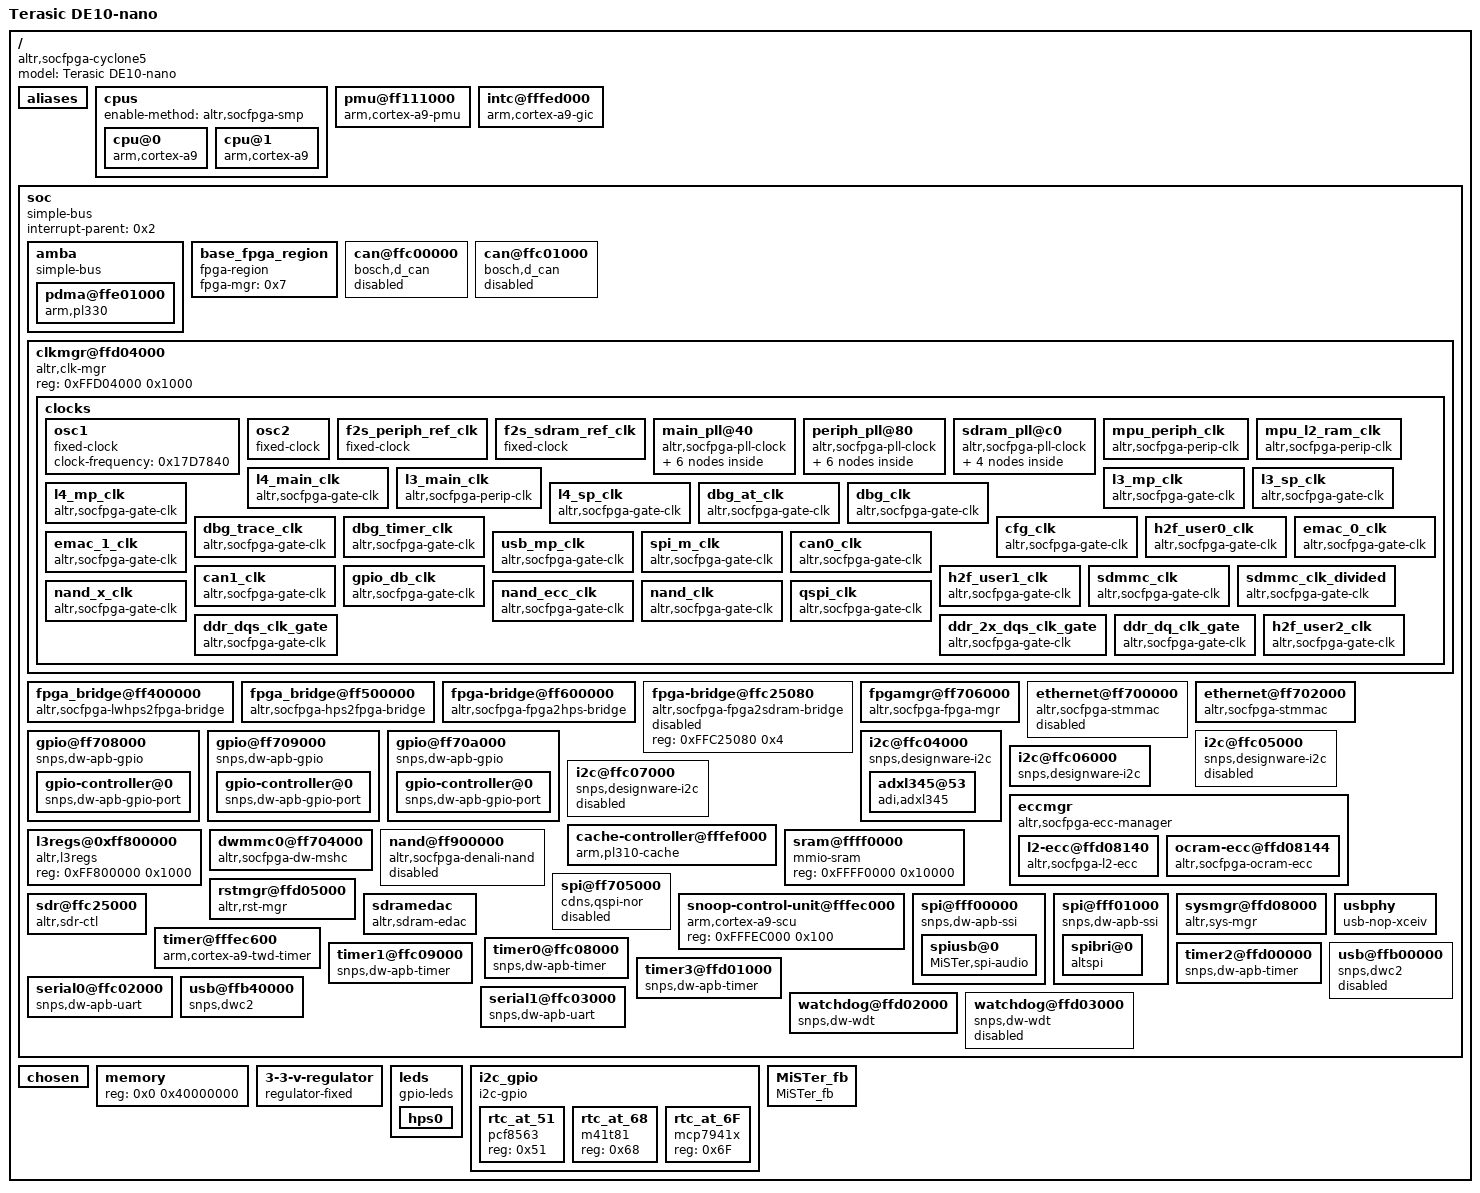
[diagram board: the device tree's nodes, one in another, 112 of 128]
/dts-v1/;
// version: 17
// last_comp_version: 16
// boot_cpuid_phys: 0x0

/memreserve/ 0 0x1000;
/ {
    #address-cells = <0x1>;
    #size-cells = <0x1>;
    model = "Terasic DE10-nano";
    compatible = "altr,socfpga-cyclone5", "altr,socfpga";
    aliases {
        serial0 = "/soc/serial0@ffc02000";
        serial1 = "/soc/serial1@ffc03000";
        timer0 = "/soc/timer0@ffc08000";
        timer1 = "/soc/timer1@ffc09000";
        timer2 = "/soc/timer2@ffd00000";
        timer3 = "/soc/timer3@ffd01000";
        ethernet0 = "/soc/ethernet@ff702000";
    };
    cpus {
        #address-cells = <0x1>;
        #size-cells = <0x0>;
        enable-method = "altr,socfpga-smp";
        cpu@0 {
            compatible = "arm,cortex-a9";
            device_type = "cpu";
            reg = <0x0>;
            next-level-cache = <0x1>;
            phandle = <0x3>;
        };
        cpu@1 {
            compatible = "arm,cortex-a9";
            device_type = "cpu";
            reg = <0x1>;
            next-level-cache = <0x1>;
            phandle = <0x4>;
        };
    };
    pmu@ff111000 {
        compatible = "arm,cortex-a9-pmu";
        interrupt-parent = <0x2>;
        interrupts = <0x0 0xB0 0x4 0x0 0xB1 0x4>;
        interrupt-affinity = <0x3 0x4>;
        reg = <0xFF111000 0x1000 0xFF113000 0x1000>;
    };
    intc@fffed000 {
        compatible = "arm,cortex-a9-gic";
        #interrupt-cells = <0x3>;
        interrupt-controller;
        reg = <0xFFFED000 0x1000 0xFFFEC100 0x100>;
        phandle = <0x2>;
    };
    soc {
        #address-cells = <0x1>;
        #size-cells = <0x1>;
        compatible = "simple-bus";
        device_type = "soc";
        interrupt-parent = <0x2>;
        ranges;
        amba {
            compatible = "simple-bus";
            #address-cells = <0x1>;
            #size-cells = <0x1>;
            ranges;
            pdma@ffe01000 {
                compatible = "arm,pl330", "arm,primecell";
                reg = <0xFFE01000 0x1000>;
                interrupts = <0x0 0x68 0x4 0x0 0x69 0x4 0x0 0x6A 0x4 0x0 0x6B 0x4 0x0 0x6C 0x4 0x0 0x6D 0x4 0x0 0x6E 0x4 0x0 0x6F 0x4>;
                #dma-cells = <0x1>;
                #dma-channels = <0x8>;
                #dma-requests = <0x20>;
                clocks = <0x5>;
                clock-names = "apb_pclk";
                resets = <0x6 0x3C>;
                reset-names = "dma";
            };
        };
        base_fpga_region {
            compatible = "fpga-region";
            fpga-mgr = <0x7>;
            #address-cells = <0x1>;
            #size-cells = <0x1>;
        };
        can@ffc00000 {
            compatible = "bosch,d_can";
            reg = <0xFFC00000 0x1000>;
            interrupts = <0x0 0x83 0x4 0x0 0x84 0x4 0x0 0x85 0x4 0x0 0x86 0x4>;
            clocks = <0x8>;
            resets = <0x6 0x37>;
            status = "disabled";
        };
        can@ffc01000 {
            compatible = "bosch,d_can";
            reg = <0xFFC01000 0x1000>;
            interrupts = <0x0 0x87 0x4 0x0 0x88 0x4 0x0 0x89 0x4 0x0 0x8A 0x4>;
            clocks = <0x9>;
            resets = <0x6 0x38>;
            status = "disabled";
        };
        clkmgr@ffd04000 {
            compatible = "altr,clk-mgr";
            reg = <0xFFD04000 0x1000>;
            clocks {
                #address-cells = <0x1>;
                #size-cells = <0x0>;
                osc1 {
                    #clock-cells = <0x0>;
                    compatible = "fixed-clock";
                    clock-frequency = <0x17D7840>;
                    phandle = <0xA>;
                };
                osc2 {
                    #clock-cells = <0x0>;
                    compatible = "fixed-clock";
                    phandle = <0xC>;
                };
                f2s_periph_ref_clk {
                    #clock-cells = <0x0>;
                    compatible = "fixed-clock";
                    phandle = <0xD>;
                };
                f2s_sdram_ref_clk {
                    #clock-cells = <0x0>;
                    compatible = "fixed-clock";
                    phandle = <0xF>;
                };
                main_pll@40 {
                    #address-cells = <0x1>;
                    #size-cells = <0x0>;
                    #clock-cells = <0x0>;
                    compatible = "altr,socfpga-pll-clock";
                    clocks = <0xA>;
                    reg = <0x40>;
                    phandle = <0xB>;
                    mpuclk@48 {
                        #clock-cells = <0x0>;
                        compatible = "altr,socfpga-perip-clk";
                        clocks = <0xB>;
                        div-reg = <0xE0 0x0 0x9>;
                        reg = <0x48>;
                        phandle = <0x11>;
                    };
                    mainclk@4c {
                        #clock-cells = <0x0>;
                        compatible = "altr,socfpga-perip-clk";
                        clocks = <0xB>;
                        div-reg = <0xE4 0x0 0x9>;
                        reg = <0x4C>;
                        phandle = <0x12>;
                    };
                    dbg_base_clk@50 {
                        #clock-cells = <0x0>;
                        compatible = "altr,socfpga-perip-clk";
                        clocks = <0xB 0xA>;
                        div-reg = <0xE8 0x0 0x9>;
                        reg = <0x50>;
                        phandle = <0x15>;
                    };
                    main_qspi_clk@54 {
                        #clock-cells = <0x0>;
                        compatible = "altr,socfpga-perip-clk";
                        clocks = <0xB>;
                        reg = <0x54>;
                        phandle = <0x1F>;
                    };
                    main_nand_sdmmc_clk@58 {
                        #clock-cells = <0x0>;
                        compatible = "altr,socfpga-perip-clk";
                        clocks = <0xB>;
                        reg = <0x58>;
                        phandle = <0x1B>;
                    };
                    cfg_h2f_usr0_clk@5c {
                        #clock-cells = <0x0>;
                        compatible = "altr,socfpga-perip-clk";
                        clocks = <0xB>;
                        reg = <0x5C>;
                        phandle = <0x17>;
                    };
                };
                periph_pll@80 {
                    #address-cells = <0x1>;
                    #size-cells = <0x0>;
                    #clock-cells = <0x0>;
                    compatible = "altr,socfpga-pll-clock";
                    clocks = <0xA 0xC 0xD>;
                    reg = <0x80>;
                    phandle = <0xE>;
                    emac0_clk@88 {
                        #clock-cells = <0x0>;
                        compatible = "altr,socfpga-perip-clk";
                        clocks = <0xE>;
                        reg = <0x88>;
                        phandle = <0x18>;
                    };
                    emac1_clk@8c {
                        #clock-cells = <0x0>;
                        compatible = "altr,socfpga-perip-clk";
                        clocks = <0xE>;
                        reg = <0x8C>;
                        phandle = <0x19>;
                    };
                    per_qsi_clk@90 {
                        #clock-cells = <0x0>;
                        compatible = "altr,socfpga-perip-clk";
                        clocks = <0xE>;
                        reg = <0x90>;
                        phandle = <0x20>;
                    };
                    per_nand_mmc_clk@94 {
                        #clock-cells = <0x0>;
                        compatible = "altr,socfpga-perip-clk";
                        clocks = <0xE>;
                        reg = <0x94>;
                        phandle = <0x1C>;
                    };
                    per_base_clk@98 {
                        #clock-cells = <0x0>;
                        compatible = "altr,socfpga-perip-clk";
                        clocks = <0xE>;
                        reg = <0x98>;
                        phandle = <0x14>;
                    };
                    h2f_usr1_clk@9c {
                        #clock-cells = <0x0>;
                        compatible = "altr,socfpga-perip-clk";
                        clocks = <0xE>;
                        reg = <0x9C>;
                        phandle = <0x1A>;
                    };
                };
                sdram_pll@c0 {
                    #address-cells = <0x1>;
                    #size-cells = <0x0>;
                    #clock-cells = <0x0>;
                    compatible = "altr,socfpga-pll-clock";
                    clocks = <0xA 0xC 0xF>;
                    reg = <0xC0>;
                    phandle = <0x10>;
                    ddr_dqs_clk@c8 {
                        #clock-cells = <0x0>;
                        compatible = "altr,socfpga-perip-clk";
                        clocks = <0x10>;
                        reg = <0xC8>;
                        phandle = <0x21>;
                    };
                    ddr_2x_dqs_clk@cc {
                        #clock-cells = <0x0>;
                        compatible = "altr,socfpga-perip-clk";
                        clocks = <0x10>;
                        reg = <0xCC>;
                        phandle = <0x22>;
                    };
                    ddr_dq_clk@d0 {
                        #clock-cells = <0x0>;
                        compatible = "altr,socfpga-perip-clk";
                        clocks = <0x10>;
                        reg = <0xD0>;
                        phandle = <0x23>;
                    };
                    h2f_usr2_clk@d4 {
                        #clock-cells = <0x0>;
                        compatible = "altr,socfpga-perip-clk";
                        clocks = <0x10>;
                        reg = <0xD4>;
                        phandle = <0x24>;
                    };
                };
                mpu_periph_clk {
                    #clock-cells = <0x0>;
                    compatible = "altr,socfpga-perip-clk";
                    clocks = <0x11>;
                    fixed-divider = <0x4>;
                    phandle = <0x33>;
                };
                mpu_l2_ram_clk {
                    #clock-cells = <0x0>;
                    compatible = "altr,socfpga-perip-clk";
                    clocks = <0x11>;
                    fixed-divider = <0x2>;
                };
                l4_main_clk {
                    #clock-cells = <0x0>;
                    compatible = "altr,socfpga-gate-clk";
                    clocks = <0x12>;
                    clk-gate = <0x60 0x0>;
                    phandle = <0x5>;
                };
                l3_main_clk {
                    #clock-cells = <0x0>;
                    compatible = "altr,socfpga-perip-clk";
                    clocks = <0x12>;
                    fixed-divider = <0x1>;
                };
                l3_mp_clk {
                    #clock-cells = <0x0>;
                    compatible = "altr,socfpga-gate-clk";
                    clocks = <0x12>;
                    div-reg = <0x64 0x0 0x2>;
                    clk-gate = <0x60 0x1>;
                    phandle = <0x13>;
                };
                l3_sp_clk {
                    #clock-cells = <0x0>;
                    compatible = "altr,socfpga-gate-clk";
                    clocks = <0x13>;
                    div-reg = <0x64 0x2 0x2>;
                };
                l4_mp_clk {
                    #clock-cells = <0x0>;
                    compatible = "altr,socfpga-gate-clk";
                    clocks = <0x12 0x14>;
                    div-reg = <0x64 0x4 0x3>;
                    clk-gate = <0x60 0x2>;
                    phandle = <0x28>;
                };
                l4_sp_clk {
                    #clock-cells = <0x0>;
                    compatible = "altr,socfpga-gate-clk";
                    clocks = <0x12 0x14>;
                    div-reg = <0x64 0x7 0x3>;
                    clk-gate = <0x60 0x3>;
                    phandle = <0x29>;
                };
                dbg_at_clk {
                    #clock-cells = <0x0>;
                    compatible = "altr,socfpga-gate-clk";
                    clocks = <0x15>;
                    div-reg = <0x68 0x0 0x2>;
                    clk-gate = <0x60 0x4>;
                    phandle = <0x16>;
                };
                dbg_clk {
                    #clock-cells = <0x0>;
                    compatible = "altr,socfpga-gate-clk";
                    clocks = <0x16>;
                    div-reg = <0x68 0x2 0x2>;
                    clk-gate = <0x60 0x5>;
                };
                dbg_trace_clk {
                    #clock-cells = <0x0>;
                    compatible = "altr,socfpga-gate-clk";
                    clocks = <0x15>;
                    div-reg = <0x6C 0x0 0x3>;
                    clk-gate = <0x60 0x6>;
                };
                dbg_timer_clk {
                    #clock-cells = <0x0>;
                    compatible = "altr,socfpga-gate-clk";
                    clocks = <0x15>;
                    clk-gate = <0x60 0x7>;
                };
                cfg_clk {
                    #clock-cells = <0x0>;
                    compatible = "altr,socfpga-gate-clk";
                    clocks = <0x17>;
                    clk-gate = <0x60 0x8>;
                };
                h2f_user0_clk {
                    #clock-cells = <0x0>;
                    compatible = "altr,socfpga-gate-clk";
                    clocks = <0x17>;
                    clk-gate = <0x60 0x9>;
                };
                emac_0_clk {
                    #clock-cells = <0x0>;
                    compatible = "altr,socfpga-gate-clk";
                    clocks = <0x18>;
                    clk-gate = <0xA0 0x0>;
                    phandle = <0x26>;
                };
                emac_1_clk {
                    #clock-cells = <0x0>;
                    compatible = "altr,socfpga-gate-clk";
                    clocks = <0x19>;
                    clk-gate = <0xA0 0x1>;
                    phandle = <0x27>;
                };
                usb_mp_clk {
                    #clock-cells = <0x0>;
                    compatible = "altr,socfpga-gate-clk";
                    clocks = <0x14>;
                    clk-gate = <0xA0 0x2>;
                    div-reg = <0xA4 0x0 0x3>;
                    phandle = <0x34>;
                };
                spi_m_clk {
                    #clock-cells = <0x0>;
                    compatible = "altr,socfpga-gate-clk";
                    clocks = <0x14>;
                    clk-gate = <0xA0 0x3>;
                    div-reg = <0xA4 0x3 0x3>;
                    phandle = <0x32>;
                };
                can0_clk {
                    #clock-cells = <0x0>;
                    compatible = "altr,socfpga-gate-clk";
                    clocks = <0x14>;
                    clk-gate = <0xA0 0x4>;
                    div-reg = <0xA4 0x6 0x3>;
                    phandle = <0x8>;
                };
                can1_clk {
                    #clock-cells = <0x0>;
                    compatible = "altr,socfpga-gate-clk";
                    clocks = <0x14>;
                    clk-gate = <0xA0 0x5>;
                    div-reg = <0xA4 0x9 0x3>;
                    phandle = <0x9>;
                };
                gpio_db_clk {
                    #clock-cells = <0x0>;
                    compatible = "altr,socfpga-gate-clk";
                    clocks = <0x14>;
                    clk-gate = <0xA0 0x6>;
                    div-reg = <0xA8 0x0 0x18>;
                };
                h2f_user1_clk {
                    #clock-cells = <0x0>;
                    compatible = "altr,socfpga-gate-clk";
                    clocks = <0x1A>;
                    clk-gate = <0xA0 0x7>;
                };
                sdmmc_clk {
                    #clock-cells = <0x0>;
                    compatible = "altr,socfpga-gate-clk";
                    clocks = <0xD 0x1B 0x1C>;
                    clk-gate = <0xA0 0x8>;
                    clk-phase = <0x0 0x87>;
                    phandle = <0x1D>;
                };
                sdmmc_clk_divided {
                    #clock-cells = <0x0>;
                    compatible = "altr,socfpga-gate-clk";
                    clocks = <0x1D>;
                    clk-gate = <0xA0 0x8>;
                    fixed-divider = <0x4>;
                    phandle = <0x2C>;
                };
                nand_x_clk {
                    #clock-cells = <0x0>;
                    compatible = "altr,socfpga-gate-clk";
                    clocks = <0xD 0x1B 0x1C>;
                    clk-gate = <0xA0 0x9>;
                    phandle = <0x1E>;
                };
                nand_ecc_clk {
                    #clock-cells = <0x0>;
                    compatible = "altr,socfpga-gate-clk";
                    clocks = <0x1E>;
                    clk-gate = <0xA0 0x9>;
                    phandle = <0x2F>;
                };
                nand_clk {
                    #clock-cells = <0x0>;
                    compatible = "altr,socfpga-gate-clk";
                    clocks = <0x1E>;
                    clk-gate = <0xA0 0xA>;
                    fixed-divider = <0x4>;
                    phandle = <0x2E>;
                };
                qspi_clk {
                    #clock-cells = <0x0>;
                    compatible = "altr,socfpga-gate-clk";
                    clocks = <0xD 0x1F 0x20>;
                    clk-gate = <0xA0 0xB>;
                    phandle = <0x30>;
                };
                ddr_dqs_clk_gate {
                    #clock-cells = <0x0>;
                    compatible = "altr,socfpga-gate-clk";
                    clocks = <0x21>;
                    clk-gate = <0xD8 0x0>;
                };
                ddr_2x_dqs_clk_gate {
                    #clock-cells = <0x0>;
                    compatible = "altr,socfpga-gate-clk";
                    clocks = <0x22>;
                    clk-gate = <0xD8 0x1>;
                };
                ddr_dq_clk_gate {
                    #clock-cells = <0x0>;
                    compatible = "altr,socfpga-gate-clk";
                    clocks = <0x23>;
                    clk-gate = <0xD8 0x2>;
                };
                h2f_user2_clk {
                    #clock-cells = <0x0>;
                    compatible = "altr,socfpga-gate-clk";
                    clocks = <0x24>;
                    clk-gate = <0xD8 0x3>;
                };
            };
        };
        fpga_bridge@ff400000 {
            compatible = "altr,socfpga-lwhps2fpga-bridge";
            reg = <0xFF400000 0x100000>;
            resets = <0x6 0x61>;
            clocks = <0x5>;
            status = "okay";
        };
        fpga_bridge@ff500000 {
            compatible = "altr,socfpga-hps2fpga-bridge";
            reg = <0xFF500000 0x10000>;
            resets = <0x6 0x60>;
            clocks = <0x5>;
            status = "okay";
        };
        fpga-bridge@ff600000 {
            compatible = "altr,socfpga-fpga2hps-bridge";
            reg = <0xFF600000 0x100000>;
            resets = <0x6 0x62>;
            clocks = <0x5>;
            status = "okay";
        };
        fpga-bridge@ffc25080 {
            compatible = "altr,socfpga-fpga2sdram-bridge";
            reg = <0xFFC25080 0x4>;
            status = "disabled";
        };
        fpgamgr@ff706000 {
            compatible = "altr,socfpga-fpga-mgr";
            reg = <0xFF706000 0x1000 0xFFB90000 0x4>;
            interrupts = <0x0 0xAF 0x4>;
            phandle = <0x7>;
        };
        ethernet@ff700000 {
            compatible = "altr,socfpga-stmmac", "snps,dwmac-3.70a", "snps,dwmac";
            altr,sysmgr-syscon = <0x25 0x60 0x0>;
            reg = <0xFF700000 0x2000>;
            interrupts = <0x0 0x73 0x4>;
            interrupt-names = "macirq";
            mac-address = [00 00 00 00 00 00];
            clocks = <0x26>;
            clock-names = "stmmaceth";
            resets = <0x6 0x20>;
            reset-names = "stmmaceth";
            snps,multicast-filter-bins = <0x100>;
            snps,perfect-filter-entries = <0x80>;
            tx-fifo-depth = <0x1000>;
            rx-fifo-depth = <0x1000>;
            status = "disabled";
        };
        ethernet@ff702000 {
            compatible = "altr,socfpga-stmmac", "snps,dwmac-3.70a", "snps,dwmac";
            altr,sysmgr-syscon = <0x25 0x60 0x2>;
            reg = <0xFF702000 0x2000>;
            interrupts = <0x0 0x78 0x4>;
            interrupt-names = "macirq";
            mac-address = [00 00 00 00 00 00];
            clocks = <0x27>;
            clock-names = "stmmaceth";
            resets = <0x6 0x21>;
            reset-names = "stmmaceth";
            snps,multicast-filter-bins = <0x100>;
            snps,perfect-filter-entries = <0x80>;
            tx-fifo-depth = <0x1000>;
            rx-fifo-depth = <0x1000>;
            status = "okay";
            phy-mode = "rgmii";
            txd0-skew-ps = <0x0>;
            txd1-skew-ps = <0x0>;
            txd2-skew-ps = <0x0>;
            txd3-skew-ps = <0x0>;
            rxd0-skew-ps = <0x1A4>;
            rxd1-skew-ps = <0x1A4>;
            rxd2-skew-ps = <0x1A4>;
            rxd3-skew-ps = <0x1A4>;
            txen-skew-ps = <0x0>;
            txc-skew-ps = <0x744>;
            rxdv-skew-ps = <0x1A4>;
            rxc-skew-ps = <0x690>;
            max-frame-size = <0xED8>;
        };
        gpio@ff708000 {
            #address-cells = <0x1>;
            #size-cells = <0x0>;
            compatible = "snps,dw-apb-gpio";
            reg = <0xFF708000 0x1000>;
            clocks = <0x28>;
            resets = <0x6 0x39>;
            status = "okay";
            gpio-controller@0 {
                compatible = "snps,dw-apb-gpio-port";
                gpio-controller;
                #gpio-cells = <0x2>;
                snps,nr-gpios = <0x1D>;
                reg = <0x0>;
                interrupt-controller;
                #interrupt-cells = <0x2>;
                interrupts = <0x0 0xA4 0x4>;
            };
        };
        gpio@ff709000 {
            #address-cells = <0x1>;
            #size-cells = <0x0>;
            compatible = "snps,dw-apb-gpio";
            reg = <0xFF709000 0x1000>;
            clocks = <0x28>;
            resets = <0x6 0x3A>;
            status = "okay";
            gpio-controller@0 {
                compatible = "snps,dw-apb-gpio-port";
                gpio-controller;
                #gpio-cells = <0x2>;
                snps,nr-gpios = <0x1D>;
                reg = <0x0>;
                interrupt-controller;
                #interrupt-cells = <0x2>;
                interrupts = <0x0 0xA5 0x4>;
                phandle = <0x36>;
            };
        };
        gpio@ff70a000 {
            #address-cells = <0x1>;
            #size-cells = <0x0>;
            compatible = "snps,dw-apb-gpio";
            reg = <0xFF70A000 0x1000>;
            clocks = <0x28>;
            resets = <0x6 0x3B>;
            status = "okay";
            gpio-controller@0 {
                compatible = "snps,dw-apb-gpio-port";
                gpio-controller;
                #gpio-cells = <0x2>;
                snps,nr-gpios = <0x1B>;
                reg = <0x0>;
                interrupt-controller;
                #interrupt-cells = <0x2>;
                interrupts = <0x0 0xA6 0x4>;
                phandle = <0x2A>;
            };
        };
        i2c@ffc04000 {
            #address-cells = <0x1>;
            #size-cells = <0x0>;
            compatible = "snps,designware-i2c";
            reg = <0xFFC04000 0x1000>;
            resets = <0x6 0x2C>;
            clocks = <0x29>;
            interrupts = <0x0 0x9E 0x4>;
            status = "okay";
            speed-mode = <0x0>;
            adxl345@53 {
                compatible = "adi,adxl345";
                reg = <0x53>;
                interrupt-parent = <0x2A>;
                interrupts = <0x3 0x2>;
            };
        };
        i2c@ffc05000 {
            #address-cells = <0x1>;
            #size-cells = <0x0>;
            clock-frequency = <0x186A0>;
            compatible = "snps,designware-i2c";
            reg = <0xFFC05000 0x1000>;
            resets = <0x6 0x2D>;
            clocks = <0x29>;
            interrupts = <0x0 0x9F 0x4>;
            status = "disabled";
        };
        i2c@ffc06000 {
            #address-cells = <0x1>;
            #size-cells = <0x0>;
            compatible = "snps,designware-i2c";
            reg = <0xFFC06000 0x1000>;
            resets = <0x6 0x2E>;
            clocks = <0x29>;
            interrupts = <0x0 0xA0 0x4>;
            status = "okay";
            clock-frequency = <0x186A0>;
            speed-mode = <0x0>;
        };
        i2c@ffc07000 {
            #address-cells = <0x1>;
            #size-cells = <0x0>;
            compatible = "snps,designware-i2c";
            reg = <0xFFC07000 0x1000>;
            resets = <0x6 0x2F>;
            clocks = <0x29>;
            interrupts = <0x0 0xA1 0x4>;
            status = "disabled";
        };
        eccmgr {
            compatible = "altr,socfpga-ecc-manager";
            #address-cells = <0x1>;
            #size-cells = <0x1>;
            ranges;
            l2-ecc@ffd08140 {
                compatible = "altr,socfpga-l2-ecc";
                reg = <0xFFD08140 0x4>;
                interrupts = <0x0 0x24 0x1 0x0 0x25 0x1>;
            };
            ocram-ecc@ffd08144 {
                compatible = "altr,socfpga-ocram-ecc";
                reg = <0xFFD08144 0x4>;
                iram = <0x2B>;
                interrupts = <0x0 0xB2 0x1 0x0 0xB3 0x1>;
            };
        };
        cache-controller@fffef000 {
            compatible = "arm,pl310-cache";
            reg = <0xFFFEF000 0x1000>;
            interrupts = <0x0 0x26 0x4>;
            cache-unified;
            cache-level = <0x2>;
            arm,tag-latency = <0x1 0x1 0x1>;
            arm,data-latency = <0x2 0x1 0x1>;
            prefetch-data = <0x1>;
            prefetch-instr = <0x1>;
            arm,shared-override;
            arm,double-linefill = <0x1>;
            arm,double-linefill-incr = <0x0>;
            arm,double-linefill-wrap = <0x1>;
            arm,prefetch-drop = <0x0>;
            arm,prefetch-offset = <0x7>;
            phandle = <0x1>;
        };
        l3regs@0xff800000 {
            compatible = "altr,l3regs", "syscon";
            reg = <0xFF800000 0x1000>;
        };
        dwmmc0@ff704000 {
            compatible = "altr,socfpga-dw-mshc";
            reg = <0xFF704000 0x1000>;
            interrupts = <0x0 0x8B 0x4>;
            fifo-depth = <0x400>;
            #address-cells = <0x1>;
            #size-cells = <0x0>;
            clocks = <0x28 0x2C>;
            clock-names = "biu", "ciu";
            resets = <0x6 0x36>;
            status = "okay";
            broken-cd;
            bus-width = <0x4>;
            cap-mmc-highspeed;
            cap-sd-highspeed;
            vmmc-supply = <0x2D>;
            vqmmc-supply = <0x2D>;
        };
        nand@ff900000 {
            #address-cells = <0x1>;
            #size-cells = <0x0>;
            compatible = "altr,socfpga-denali-nand";
            reg = <0xFF900000 0x100000 0xFFB80000 0x10000>;
            reg-names = "nand_data", "denali_reg";
            interrupts = <0x0 0x90 0x4>;
            clocks = <0x2E 0x1E 0x2F>;
            clock-names = "nand", "nand_x", "ecc";
            resets = <0x6 0x24>;
            status = "disabled";
        };
        sram@ffff0000 {
            compatible = "mmio-sram";
            reg = <0xFFFF0000 0x10000>;
            phandle = <0x2B>;
        };
        spi@ff705000 {
            compatible = "cdns,qspi-nor";
            #address-cells = <0x1>;
            #size-cells = <0x0>;
            reg = <0xFF705000 0x1000 0xFFA00000 0x1000>;
            interrupts = <0x0 0x97 0x4>;
            cdns,fifo-depth = <0x80>;
            cdns,fifo-width = <0x4>;
            cdns,trigger-address = <0x0>;
            clocks = <0x30>;
            resets = <0x6 0x25>;
            status = "disabled";
        };
        rstmgr@ffd05000 {
            #reset-cells = <0x1>;
            compatible = "altr,rst-mgr";
            reg = <0xFFD05000 0x1000>;
            altr,modrst-offset = <0x10>;
            phandle = <0x6>;
        };
        snoop-control-unit@fffec000 {
            compatible = "arm,cortex-a9-scu";
            reg = <0xFFFEC000 0x100>;
        };
        sdr@ffc25000 {
            compatible = "altr,sdr-ctl", "syscon";
            reg = <0xFFC25000 0x1000>;
            resets = <0x6 0x3D>;
            phandle = <0x31>;
        };
        sdramedac {
            compatible = "altr,sdram-edac";
            altr,sdr-syscon = <0x31>;
            interrupts = <0x0 0x27 0x4>;
        };
        spi@fff00000 {
            compatible = "snps,dw-apb-ssi";
            #address-cells = <0x1>;
            #size-cells = <0x0>;
            reg = <0xFFF00000 0x1000>;
            interrupts = <0x0 0x9A 0x4>;
            num-cs = <0x4>;
            clocks = <0x32>;
            resets = <0x6 0x32>;
            reset-names = "spi";
            status = "okay";
            timeouts = <0x3>;
            spiusb@0 {
                compatible = "MiSTer,spi-audio";
                reg = <0x0>;
                spi-max-frequency = <0x989680>;
                spi-cpha;
                spi-cpol;
                status = "okay";
            };
        };
        spi@fff01000 {
            compatible = "snps,dw-apb-ssi";
            #address-cells = <0x1>;
            #size-cells = <0x0>;
            reg = <0xFFF01000 0x1000>;
            interrupts = <0x0 0x9B 0x4>;
            num-cs = <0x4>;
            clocks = <0x32>;
            resets = <0x6 0x33>;
            reset-names = "spi";
            status = "okay";
            timeouts = <0x3>;
            spibri@0 {
                status = "okay";
                compatible = "altspi";
                spi-max-frequency = <0x17D7840>;
                reg = <0x0>;
            };
        };
        sysmgr@ffd08000 {
            compatible = "altr,sys-mgr", "syscon";
            reg = <0xFFD08000 0x4000>;
            cpu1-start-addr = <0xFFD080C4>;
            phandle = <0x25>;
        };
        timer@fffec600 {
            compatible = "arm,cortex-a9-twd-timer";
            reg = <0xFFFEC600 0x100>;
            interrupts = <0x1 0xD 0xF01>;
            clocks = <0x33>;
        };
        timer0@ffc08000 {
            compatible = "snps,dw-apb-timer";
            interrupts = <0x0 0xA7 0x4>;
            reg = <0xFFC08000 0x1000>;
            clocks = <0x29>;
            clock-names = "timer";
            resets = <0x6 0x2A>;
            reset-names = "timer";
        };
        timer1@ffc09000 {
            compatible = "snps,dw-apb-timer";
            interrupts = <0x0 0xA8 0x4>;
            reg = <0xFFC09000 0x1000>;
            clocks = <0x29>;
            clock-names = "timer";
            resets = <0x6 0x2B>;
            reset-names = "timer";
        };
        timer2@ffd00000 {
            compatible = "snps,dw-apb-timer";
            interrupts = <0x0 0xA9 0x4>;
            reg = <0xFFD00000 0x1000>;
            clocks = <0xA>;
            clock-names = "timer";
            resets = <0x6 0x28>;
            reset-names = "timer";
        };
        timer3@ffd01000 {
            compatible = "snps,dw-apb-timer";
            interrupts = <0x0 0xAA 0x4>;
            reg = <0xFFD01000 0x1000>;
            clocks = <0xA>;
            clock-names = "timer";
            resets = <0x6 0x29>;
            reset-names = "timer";
        };
        serial0@ffc02000 {
            compatible = "snps,dw-apb-uart";
            reg = <0xFFC02000 0x1000>;
            interrupts = <0x0 0xA2 0x4>;
            reg-shift = <0x2>;
            reg-io-width = <0x4>;
            clocks = <0x29>;
            resets = <0x6 0x30>;
            status = "okay";
        };
        serial1@ffc03000 {
            compatible = "snps,dw-apb-uart";
            reg = <0xFFC03000 0x1000>;
            interrupts = <0x0 0xA3 0x4>;
            reg-shift = <0x2>;
            reg-io-width = <0x4>;
            clocks = <0x29>;
            resets = <0x6 0x31>;
            status = "okay";
        };
        usbphy {
            #phy-cells = <0x0>;
            compatible = "usb-nop-xceiv";
            status = "okay";
            phandle = <0x35>;
        };
        usb@ffb00000 {
            compatible = "snps,dwc2";
            reg = <0xFFB00000 0xFFFF>;
            interrupts = <0x0 0x7D 0x4>;
            clocks = <0x34>;
            clock-names = "otg";
            resets = <0x6 0x22>;
            reset-names = "dwc2";
            phys = <0x35>;
            phy-names = "usb2-phy";
            status = "disabled";
        };
        usb@ffb40000 {
            compatible = "snps,dwc2";
            reg = <0xFFB40000 0xFFFF>;
            interrupts = <0x0 0x80 0x4>;
            clocks = <0x34>;
            clock-names = "otg";
            resets = <0x6 0x23>;
            reset-names = "dwc2";
            phys = <0x35>;
            phy-names = "usb2-phy";
            status = "okay";
            disable-over-current;
            dr_mode = "host";
        };
        watchdog@ffd02000 {
            compatible = "snps,dw-wdt";
            reg = <0xFFD02000 0x1000>;
            interrupts = <0x0 0xAB 0x4>;
            clocks = <0xA>;
            resets = <0x6 0x26>;
            status = "okay";
        };
        watchdog@ffd03000 {
            compatible = "snps,dw-wdt";
            reg = <0xFFD03000 0x1000>;
            interrupts = <0x0 0xAC 0x4>;
            clocks = <0xA>;
            resets = <0x6 0x27>;
            status = "disabled";
        };
    };
    chosen {
        bootargs = "earlyprintk";
        stdout-path = "serial0:115200n8";
    };
    memory {
        device_type = "memory";
        reg = <0x0 0x40000000>;
    };
    3-3-v-regulator {
        compatible = "regulator-fixed";
        regulator-name = "3.3V";
        regulator-min-microvolt = <0x325AA0>;
        regulator-max-microvolt = <0x325AA0>;
        phandle = <0x2D>;
    };
    leds {
        compatible = "gpio-leds";
        hps0 {
            label = "hps_led0";
            gpios = <0x36 0x18 0x0>;
            linux,default-trigger = "mmc0";
        };
    };
    i2c_gpio {
        #address-cells = <0x1>;
        #size-cells = <0x0>;
        compatible = "i2c-gpio";
        gpios = <0x36 0x16 0x6 0x36 0x17 0x6>;
        i2c-gpio,delay-us = <0x2>;
        rtc_at_51 {
            compatible = "pcf8563";
            reg = <0x51>;
        };
        rtc_at_68 {
            compatible = "m41t81";
            reg = <0x68>;
        };
        rtc_at_6F {
            compatible = "mcp7941x";
            reg = <0x6F>;
        };
    };
    MiSTer_fb {
        compatible = "MiSTer_fb";
        reg = <0x22000000 0x800000>;
        interrupt-parent = <0x2>;
        interrupts = <0x0 0x28 0x1>;
    };
};
